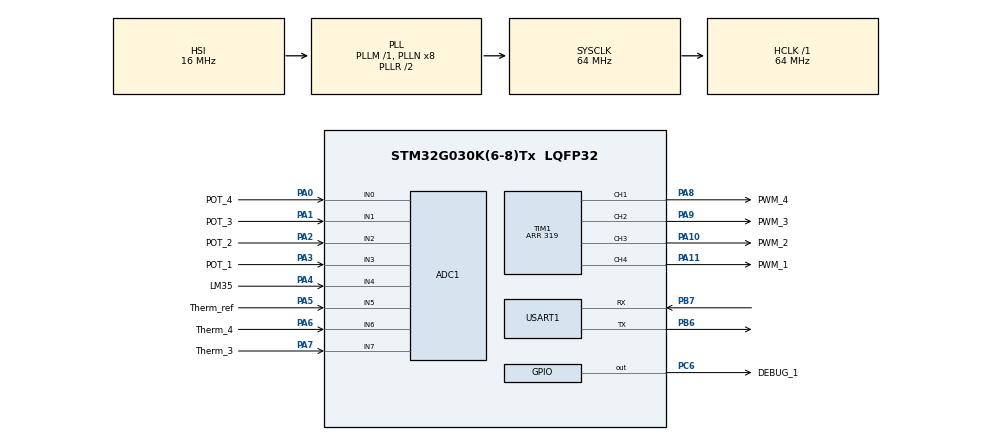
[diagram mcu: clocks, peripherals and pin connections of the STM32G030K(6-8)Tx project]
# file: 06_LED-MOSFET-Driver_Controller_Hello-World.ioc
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ADC1.Channel-0\#ChannelRegularConversion=ADC_CHANNEL_0
ADC1.Channel-1\#ChannelRegularConversion=ADC_CHANNEL_1
ADC1.Channel-2\#ChannelRegularConversion=ADC_CHANNEL_2
ADC1.Channel-3\#ChannelRegularConversion=ADC_CHANNEL_3
ADC1.Channel-4\#ChannelRegularConversion=ADC_CHANNEL_4
ADC1.Channel-5\#ChannelRegularConversion=ADC_CHANNEL_5
ADC1.Channel-6\#ChannelRegularConversion=ADC_CHANNEL_6
ADC1.Channel-7\#ChannelRegularConversion=ADC_CHANNEL_7
ADC1.ContinuousConvMode=ENABLE
ADC1.DMAContinuousRequests=ENABLE
ADC1.NbrOfConversion=8
ADC1.NbrOfConversionFlag=1
ADC1.Rank-0\#ChannelRegularConversion=1
ADC1.Rank-1\#ChannelRegularConversion=2
ADC1.Rank-2\#ChannelRegularConversion=3
ADC1.Rank-3\#ChannelRegularConversion=4
ADC1.Rank-4\#ChannelRegularConversion=5
ADC1.Rank-5\#ChannelRegularConversion=6
ADC1.Rank-6\#ChannelRegularConversion=7
ADC1.Rank-7\#ChannelRegularConversion=8
ADC1.SamplingTime-0\#ChannelRegularConversion=ADC_SAMPLINGTIME_COMMON_1
ADC1.SamplingTime-1\#ChannelRegularConversion=ADC_SAMPLINGTIME_COMMON_1
ADC1.SamplingTime-2\#ChannelRegularConversion=ADC_SAMPLINGTIME_COMMON_1
ADC1.SamplingTime-3\#ChannelRegularConversion=ADC_SAMPLINGTIME_COMMON_1
ADC1.SamplingTime-4\#ChannelRegularConversion=ADC_SAMPLINGTIME_COMMON_1
ADC1.SamplingTime-5\#ChannelRegularConversion=ADC_SAMPLINGTIME_COMMON_2
ADC1.SamplingTime-6\#ChannelRegularConversion=ADC_SAMPLINGTIME_COMMON_2
ADC1.SamplingTime-7\#ChannelRegularConversion=ADC_SAMPLINGTIME_COMMON_2
ADC1.SamplingTimeCommon1=ADC_SAMPLETIME_12CYCLES_5
ADC1.SamplingTimeCommon2=ADC_SAMPLETIME_160CYCLES_5
ADC1.SelectedChannel=ADC_CHANNEL_0|ADC_CHANNEL_1|ADC_CHANNEL_2|ADC_CHANNEL_3|ADC_CHANNEL_4|ADC_CHANNEL_5|ADC_CHANNEL_6|ADC_CHANNEL_7
ADC1.TriggerFrequencyMode=ADC_TRIGGER_FREQ_HIGH
ADC1.master=1
Dma.ADC1.0.Direction=DMA_PERIPH_TO_MEMORY
Dma.ADC1.0.EventEnable=DISABLE
Dma.ADC1.0.Instance=DMA1_Channel1
Dma.ADC1.0.MemDataAlignment=DMA_MDATAALIGN_WORD
Dma.ADC1.0.MemInc=DMA_MINC_ENABLE
Dma.ADC1.0.Mode=DMA_CIRCULAR
Dma.ADC1.0.PeriphDataAlignment=DMA_PDATAALIGN_WORD
Dma.ADC1.0.PeriphInc=DMA_PINC_DISABLE
Dma.ADC1.0.Polarity=HAL_DMAMUX_REQ_GEN_RISING
Dma.ADC1.0.Priority=DMA_PRIORITY_LOW
Dma.ADC1.0.RequestNumber=1
Dma.ADC1.0.SignalID=NONE
Dma.ADC1.0.SyncEnable=DISABLE
Dma.ADC1.0.SyncPolarity=HAL_DMAMUX_SYNC_NO_EVENT
Dma.ADC1.0.SyncRequestNumber=1
Dma.ADC1.0.SyncSignalID=NONE
Dma.Request0=ADC1
Mcu.Family=STM32G0
Mcu.Name=STM32G030K(6-8)Tx
Mcu.Package=LQFP32
NVIC.DMA1_Channel1_IRQn=true\:0\:0\:false\:false\:true\:false\:true\:true
PA0.GPIO_Label=POT_4
PA0.Mode=IN0
PA0.Signal=ADC1_IN0
PA1.GPIO_Label=POT_3
PA1.Mode=IN1
PA1.Signal=ADC1_IN1
PA10.GPIO_Label=PWM_2
PA10.Signal=S_TIM1_CH3
PA11\ [PA9].GPIO_Label=PWM_1
PA11\ [PA9].Signal=S_TIM1_CH4
PA13.Mode=Serial_Wire
PA13.Signal=SYS_SWDIO
PA14-BOOT0.Mode=Serial_Wire
PA14-BOOT0.Signal=SYS_SWCLK
PA2.GPIO_Label=POT_2
PA2.Mode=IN2
PA2.Signal=ADC1_IN2
PA3.GPIO_Label=POT_1
PA3.Mode=IN3
PA3.Signal=ADC1_IN3
PA4.GPIO_Label=LM35
PA4.Mode=IN4
PA4.Signal=ADC1_IN4
PA5.GPIO_Label=Therm_ref
PA5.Mode=IN5
PA5.Signal=ADC1_IN5
PA6.GPIO_Label=Therm_4
PA6.Mode=IN6
PA6.Signal=ADC1_IN6
PA7.GPIO_Label=Therm_3
PA7.Mode=IN7
PA7.Signal=ADC1_IN7
PA8.GPIO_Label=PWM_4
PA8.Signal=S_TIM1_CH1
PA9.GPIO_Label=PWM_3
PA9.Signal=S_TIM1_CH2
PB0.GPIO_Label=Therm_2
PB0.Signal=ADC1_IN8
PB1.GPIO_Label=Therm_1
PB1.Signal=ADC1_IN9
PB6.Mode=Asynchronous
PB6.Signal=USART1_TX
PB7.Mode=Asynchronous
PB7.Signal=USART1_RX
PC14-OSC32_IN\ (PC14).Mode=LSE-External-Oscillator
PC14-OSC32_IN\ (PC14).Signal=RCC_OSC32_IN
PC15-OSC32_OUT\ (PC15).Mode=LSE-External-Oscillator
PC15-OSC32_OUT\ (PC15).Signal=RCC_OSC32_OUT
PC6.GPIO_Label=DEBUG_1
PC6.Signal=GPIO_Output
ProjectManager.HeapSize=0x200
ProjectManager.StackSize=0x400
ProjectManager.TargetToolchain=STM32CubeIDE
RCC.ADCFreq_Value=64000000
RCC.AHBFreq_Value=64000000
RCC.CortexFreq_Value=64000000
RCC.EXTERNAL_CLOCK_VALUE=12288000
RCC.HCLKFreq_Value=64000000
RCC.HSE_VALUE=8000000
RCC.HSI_VALUE=16000000
RCC.SYSCLKFreq_VALUE=64000000
RCC.SYSCLKSource=RCC_SYSCLKSOURCE_PLLCLK
RCC.VCOOutputFreq_Value=128000000
SH.S_TIM1_CH1.0=TIM1_CH1,PWM Generation1 CH1
SH.S_TIM1_CH2.0=TIM1_CH2,PWM Generation2 CH2
SH.S_TIM1_CH3.0=TIM1_CH3,PWM Generation3 CH3
SH.S_TIM1_CH4.0=TIM1_CH4,PWM Generation4 CH4
TIM1.AutoReloadPreload=TIM_AUTORELOAD_PRELOAD_ENABLE
TIM1.Channel-PWM\ Generation1\ CH1=TIM_CHANNEL_1
TIM1.Channel-PWM\ Generation2\ CH2=TIM_CHANNEL_2
TIM1.Channel-PWM\ Generation3\ CH3=TIM_CHANNEL_3
TIM1.Channel-PWM\ Generation4\ CH4=TIM_CHANNEL_4
TIM1.Period=319
USART1.VirtualMode-Asynchronous=VM_ASYNC
VP_TIM1_VS_ClockSourceINT.Mode=Internal
board=custom

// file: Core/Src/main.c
/* USER CODE BEGIN Header */
/**
  ******************************************************************************
  * @file           : main.c
  * @brief          : Main program body
  ******************************************************************************
  * @attention
  *
  * Copyright (c) 2025 STMicroelectronics.
  * All rights reserved.
  *
  * This software is licensed under terms that can be found in the LICENSE file
  * in the root directory of this software component.
  * If no LICENSE file comes with this software, it is provided AS-IS.
  *
  ******************************************************************************
  */
/* USER CODE END Header */
#include "main.h"
#include "adc.h"
#include "dma.h"
#include "tim.h"
#include "usart.h"
#include "gpio.h"

void SystemClock_Config(void);

int main(void)
{

  /* MCU Configuration--------------------------------------------------------*/

  /* Reset of all peripherals, Initializes the Flash interface and the Systick. */
  HAL_Init();

  /* Configure the system clock */
  SystemClock_Config();

  /* Initialize all configured peripherals */
  MX_GPIO_Init();
  MX_DMA_Init();
  MX_ADC1_Init();
  MX_TIM1_Init();
  MX_USART1_UART_Init();

  /* Infinite loop */
  /* USER CODE BEGIN WHILE */
  while (1)
  {

	  HAL_GPIO_TogglePin(DEBUG_1_GPIO_Port, DEBUG_1_Pin);
	  HAL_Delay(1000);
	  HAL_GPIO_TogglePin(DEBUG_1_GPIO_Port, DEBUG_1_Pin);
	  HAL_Delay(500);

    /* USER CODE END WHILE */

  }
}

void SystemClock_Config(void)
{
  RCC_OscInitTypeDef RCC_OscInitStruct = {0};
  RCC_ClkInitTypeDef RCC_ClkInitStruct = {0};

  /** Configure the main internal regulator output voltage
  */
  HAL_PWREx_ControlVoltageScaling(PWR_REGULATOR_VOLTAGE_SCALE1);

  /** Initializes the RCC Oscillators according to the specified parameters
  * in the RCC_OscInitTypeDef structure.
  */
  RCC_OscInitStruct.OscillatorType = RCC_OSCILLATORTYPE_HSI;
  RCC_OscInitStruct.HSIState = RCC_HSI_ON;
  RCC_OscInitStruct.HSIDiv = RCC_HSI_DIV1;
  RCC_OscInitStruct.HSICalibrationValue = RCC_HSICALIBRATION_DEFAULT;
  RCC_OscInitStruct.PLL.PLLState = RCC_PLL_ON;
  RCC_OscInitStruct.PLL.PLLSource = RCC_PLLSOURCE_HSI;
  RCC_OscInitStruct.PLL.PLLM = RCC_PLLM_DIV1;
  RCC_OscInitStruct.PLL.PLLN = 8;
  RCC_OscInitStruct.PLL.PLLP = RCC_PLLP_DIV2;
  RCC_OscInitStruct.PLL.PLLR = RCC_PLLR_DIV2;
  if (HAL_RCC_OscConfig(&RCC_OscInitStruct) != HAL_OK)
  {
    Error_Handler();
  }

  /** Initializes the CPU, AHB and APB buses clocks
  */
  RCC_ClkInitStruct.ClockType = RCC_CLOCKTYPE_HCLK|RCC_CLOCKTYPE_SYSCLK
                              |RCC_CLOCKTYPE_PCLK1;
  RCC_ClkInitStruct.SYSCLKSource = RCC_SYSCLKSOURCE_PLLCLK;
  RCC_ClkInitStruct.AHBCLKDivider = RCC_SYSCLK_DIV1;
  RCC_ClkInitStruct.APB1CLKDivider = RCC_HCLK_DIV1;

  if (HAL_RCC_ClockConfig(&RCC_ClkInitStruct, FLASH_LATENCY_2) != HAL_OK)
  {
    Error_Handler();
  }
}

void Error_Handler(void)
{
  __disable_irq();
  while (1)
  {
  }
}
